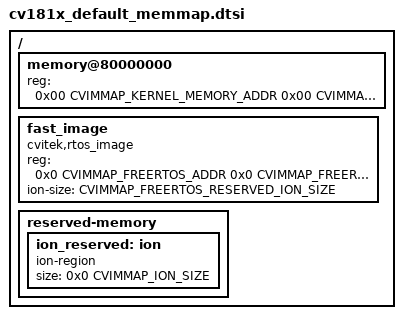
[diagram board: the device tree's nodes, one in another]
/ {
	memory@80000000 {
		device_type = "memory";
		reg = <0x00 CVIMMAP_KERNEL_MEMORY_ADDR 0x00 CVIMMAP_KERNEL_MEMORY_SIZE>;
	};


	fast_image {
		compatible = "cvitek,rtos_image";
		reg-names = "rtos_region";
		reg = <0x0 CVIMMAP_FREERTOS_ADDR 0x0 CVIMMAP_FREERTOS_SIZE>;
		ion-size = <CVIMMAP_FREERTOS_RESERVED_ION_SIZE>;	//reserved ion size for freertos
	};

	reserved-memory {
		#size-cells = <0x2>;
		#address-cells = <0x2>;
		ranges;

		ion_reserved: ion {
			compatible = "ion-region";
			size = <0x0 CVIMMAP_ION_SIZE>;
		};
	};
};
